AUTOSAR XML (schema 00046)
package /Composite_Lab
  sender receiver interface SRI_LightControl
    data LightControl: type=uint8, init-value=0
  sender receiver interface SRI_LightActuate
    data LightActuate: type=uint8, init-value=0
  sensor actuator sw component type SWC1_SA_LightControl
    provide port Pp_LightControl: provided-interface=SRI_LightControl
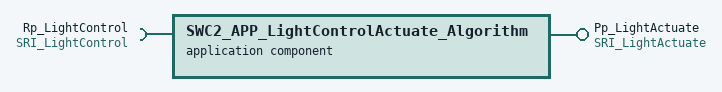
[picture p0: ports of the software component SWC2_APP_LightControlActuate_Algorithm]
  application sw component type SWC2_APP_LightControlActuate_Algorithm
    require port Rp_LightControl: required-interface=SRI_LightControl
    provide port Pp_LightActuate: provided-interface=SRI_LightActuate
  sensor actuator sw component type SWC3_SA_LightActuate
    require port Rp_LightActuate: required-interface=SRI_LightActuate
  composition sw component type SWC4_Composite1
    provide port Rp_LightActuate_Composite: provided-interface=SRI_LightActuate
    component SWC1Composite_SA_LightControl: type=SWC1_SA_LightControl
    component SWC2Composite_APP_LightControlActuate_Algorithm: type=SWC2_APP_LightControlActuate_Algorithm
    connect SWC1Composite_SA_LightControl.Pp_LightControl -> SWC2Composite_APP_LightControlActuate_Algorithm.Rp_LightControl
    delegate SWC2Composite_APP_LightControlActuate_Algorithm.Pp_LightActuate <-> outer port Rp_LightActuate_Composite
  composition sw component type SWC5_TopLevelComposite
    component SWC4_Composite_Instance: type=SWC4_Composite1
    component SWC3Composite_SA_LightActuate: type=SWC3_SA_LightActuate
    connect SWC4_Composite_Instance.Rp_LightActuate_Composite -> SWC3Composite_SA_LightActuate.Rp_LightActuate
